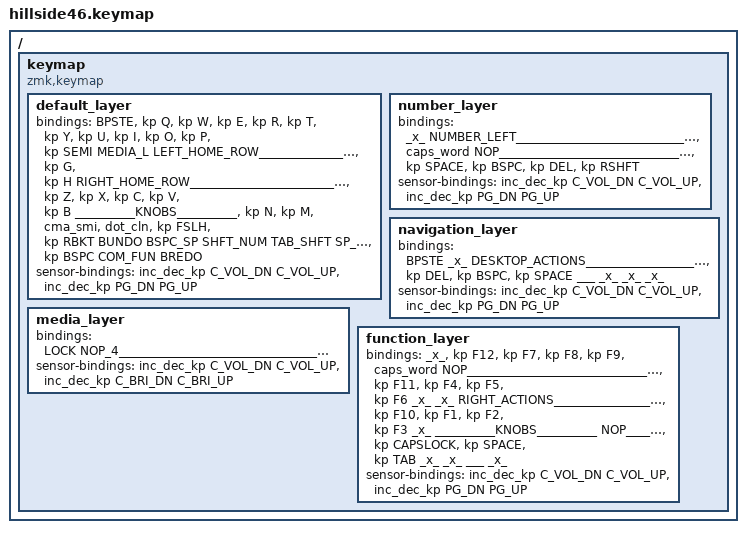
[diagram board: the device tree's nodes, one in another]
/*
 * Copyright (c) 2021-2022 The ZMK Contributors
 *
 * SPDX-License-Identifier: MIT
 */

#include <behaviors.dtsi>
#include <dt-bindings/zmk/bt.h>
#include <dt-bindings/zmk/ext_power.h>
#include <dt-bindings/zmk/keys.h>
#include <dt-bindings/zmk/outputs.h>


// layers
#define DEF     0
#define NUM     1
#define NAV     2
#define MEDIA   3
#define FUN     4

#include "keys/46.h"
#include "includes/macros.dtsi"
#include "includes/combos.dtsi"
#include "includes/behaviors.dtsi"






// Layers toggles       hold     tap
#define MEDIA_L  &ltr   MEDIA    LG(C)
#define MEDIA_R  &ltr   MEDIA    LBKT
#define SP_NAV   &ltr   NAV      SPACE
#define COM_FUN  &ltsk  FUN      LGUI   // sticky
#define SHFT_NUM &ltsk  NUM      LSHFT  // sticky

// Mod taps              hold     tap
#define BSPC_SP   &mt    SPACE    BSPC  
#define TAB_SHFT  &mt    LSHFT    TAB


// shorter codes
#define SCRSHT   &kp  LS(LG(N1))
#define LOCK     &kp  LG(LC(Q))
#define SHENTER  &kp  LS(RET)
#define BPSTE    &kp  LG(V)
#define BCPY     &kp  LG(C)
#define BCUT     &kp  LG(X)
#define BUNDO    &kp  LG(Z)
#define BREDO    &kp  LG(LS(Z))
#define BPREV    &kp  C_PREV
#define BNEXT    &kp  C_NEXT
#define BPLYPSE  &kp  C_PLAY_PAUSE
#define BMUTE    &kp  K_MUTE
#define BSTOP    &kp  C_PLAY_PAUSE
#define BVOLD    &kp  K_VOL_DN
#define BVOLU    &kp  K_VOL_UP
#define BRIUP    &kp  C_BRIGHTNESS_INC
#define BRIDOWN  &kp  C_BRIGHTNESS_DEC
#define MOVERGHT &kp  LC(RIGHT)
#define MOVELEFT &kp  LC(LEFT)
#define SHOWAPPS &kp  LC(UP)
#define MEETING  &kp  LS(LG(J))
#define BLUUSB   &out OUT_TOG // toggle keyboard output bluetooth/usb
#define ___      &trans      //  transparent
#define _x_      &none

// Home row mods
#define HRML(k1, k2, k3, k4) &hml LGUI  k1  &hml LALT  k2 &hml LCTRL k3 &hml LSHFT k4
#define HRMR(k1, k2, k3, k4) &hmr RSHFT k1  &hmr RCTRL k2 &hmr RALT  k3 &hmr RGUI  k4

// 5 Rows
#define NUMBER_TOP_ROW___________________________________  &kp N5    &kp N6    &kp N7    &kp N8    &kp N9   
#define NUMBER_BOTTOM_ROW________________________________  &kp N1    &kp N2    &kp N3    &kp N4    &kp N0
#define NOP______________________________________________    _x_       _x_       _x_       _x_       _x_  
#define PAGE_CONTROL_ROW_________________________________  &kp HOME  &kp PG_DN &kp PG_UP  &kp END  &kp INS    
#define BLUETOOTH________________________________________  &bt BT_PRV  &bt BT_NXT  &out OUT_USB  &out OUT_BLE  &bt BT_CLR_ALL 

// 4 Rows
#define NAVIGATION_____________________________            &kp LEFT  &kp DOWN   &kp UP    &kp RIGHT  
#define LEFT_ACTIONS___________________________            &kp LGUI  &kp LALT   &kp LCTRL &kp LSHFT 
#define RIGHT_ACTIONS__________________________            &kp RSHFT &kp RCTRL  &kp RALT  &kp RGUI
#define DESKTOP_ACTIONS________________________            SHOWAPPS  MOVELEFT  MOVERGHT   &kp LG(SPACE)
#define LEFT_HOME_ROW__________________________            HRML(A,        S,        D,        F)
#define RIGHT_HOME_ROW_________________________            HRMR(J,        K,        L,       SQT)
#define NOP_4__________________________________            _x_         _x_       _x_       _x_


// 3 Rows
#define VOLUME_CONTROL_______________                      BVOLD     BMUTE     BVOLU  
#define PLAY_CONTROL_________________                      BPREV    BPLYPSE    BNEXT 

// Number pad
#define NUMBER_LEFT______________________________________  &kp N1    &kp N2    &kp N3  &kp N4    &kp N5
#define NUMBER_RIGHT_____________________________________  &kp N6    &kp N7    &kp N8  &kp N9    &kp N0

// Knobs
#define __________KNOBS__________  &kp CAPSLOCK   &kp CAPSLOCK
#define _______KNOBS_MEDIA_______  BVOLD          LOCK






/ {
  keymap {
    compatible = "zmk,keymap";
    default_layer { // layer 0 (default)
      bindings = <
//  ╭──────────╭─────────────────────────────────────────────────╮                                 ╭───────────────────────────────────────────────────────────╮
//  │  PASTE   │    Q    │    W    │    E    │    R    │    T    │                                 │    Y    │    U    │    I    │    O    │    P    │   ;:    │
      BPSTE     &kp Q     &kp W     &kp E     &kp R     &kp T                                       &kp Y     &kp U     &kp I     &kp O     &kp P     &kp SEMI
//  ├──────────├─────────┼─────────┼─────────┼─────────┼─────────┤                                 ├─────────┼─────────┼─────────┼─────────┼─────────┤─────────┤
//  │ COPY/ME  │    A    │    S    │    D    │    F    │    G    │                                 │    H    │    J    │    K    │    L    │    '    │LeftBr/ME│
      MEDIA_L   LEFT_HOME_ROW__________________________ &kp G                                       &kp H     RIGHT_HOME_ROW_________________________  MEDIA_R    
//  ├──────────├─────────┼─────────┼─────────┼─────────┼─────────┤                                 ├─────────┼─────────┼─────────┼─────────┼─────────┤─────────┤
//  │   CUT    │    Z    │    X    │    C    │    V    │    B    │   ╭─────────╮     ╭─────────╮   │    N    │    M    │   ,/;   │   ./:   │    /    │ RighBr  │
        BCUT    &kp Z     &kp X     &kp C     &kp V     &kp B         __________KNOBS__________     &kp N     &kp M     &cma_smi  &dot_cln  &kp FSLH   &kp RBKT
//  ├──────────╰─────────┼─────────┼─────────┼─────────┼─────────┼   ╰─────────╯     ╰─────────╯   ┼─────────┼─────────┼─────────┼─────────┼───────────────────╯
                  BUNDO   BSPC_SP  SHFT_NUM  TAB_SHFT                                               SP_NAV  &kp BSPC    COM_FUN    BREDO
//             ╰───────────────────────────────────────╯                                           ╰───────────────────────────────────────╯
      >;

      sensor-bindings = <&inc_dec_kp C_VOL_DN C_VOL_UP &inc_dec_kp PG_DN PG_UP>;
    };


    number_layer { // layer 1 (numbers)
      bindings = <
//  ╭──────────╭─────────────────────────────────────────────────╮                                 ╭───────────────────────────────────────────────────────────╮
//  │          │                                                 │                                 │         │                                                 │ 
        _x_     NUMBER_LEFT______________________________________                                   NUMBER_RIGHT_____________________________________    _x_
//  ├──────────├─────────┼─────────┼─────────┼─────────┼─────────┤                                 ├─────────┼─────────┼─────────┼─────────┼─────────┤─────────┤
//  │          │                                                 │                                 │         │                                                 │
        _x_     NUMBER_RIGHT_____________________________________                                      _x_    RIGHT_ACTIONS__________________________   _x_   
//  ├──────────├─────────┼─────────┼─────────┼─────────┼─────────┤                                 ├─────────┼─────────┼─────────┼─────────┼─────────┤─────────┤
//  │          │                                                 │   ╭─────────╮     ╭─────────╮    │         │                                                 │
    &caps_word  NOP______________________________________________     __________KNOBS__________     NOP______________________________________________   _x_   
//  ├──────────╰─────────┼─────────┼─────────┼─────────┼─────────┼   ╰─────────╯     ╰─────────╯   ┼─────────┼─────────┼─────────┼─────────┼───────────────────╯
                   _x_       _x_       ___       _x_                                             &kp SPACE  &kp BSPC    &kp DEL   &kp RSHFT
//             ╰───────────────────────────────────────╯                                           ╰───────────────────────────────────────╯
      >;

      sensor-bindings = <&inc_dec_kp C_VOL_DN C_VOL_UP &inc_dec_kp PG_DN PG_UP>;
    };



  navigation_layer { // layer 2 (navigation)
      bindings = <
//  ╭──────────╭─────────────────────────────────────────────────╮                                 ╭───────────────────────────────────────────────────────────╮
//  │  PASTE   │         │                                       │                                 │                                                 │         │
      BPSTE        _x_    DESKTOP_ACTIONS________________________                                   NOP______________________________________________    _x_
//  ├──────────├─────────┼─────────┼─────────┼─────────┼─────────┤                                 ├─────────┼─────────┼─────────┼─────────┼─────────┤─────────┤
//  │   COPY   │                                       │         │                                 │                                       │         │         │
       BCPY     LEFT_ACTIONS___________________________   _x_                                       NAVIGATION_____________________________    _x_       _x_    
//  ├──────────├─────────┼─────────┼─────────┼─────────┼─────────┤                                 ├─────────┼─────────┼─────────┼─────────┼─────────┤─────────┤
//  │   CUT    │                                                 │   ╭─────────╮     ╭─────────╮    │                                                 │         │
        BCUT    NOP______________________________________________     __________KNOBS__________     PAGE_CONTROL_ROW_________________________________   _x_
//  ├──────────╰─────────┼─────────┼─────────┼─────────┼─────────┼   ╰─────────╯     ╰─────────╯   ┼─────────┼─────────┼─────────┼─────────┼───────────────────╯
                   _x_    &kp DEL  &kp BSPC &kp SPACE                                                  ___       _x_       _x_       _x_
//             ╰───────────────────────────────────────╯                                           ╰───────────────────────────────────────╯
      >;

      sensor-bindings = <&inc_dec_kp C_VOL_DN C_VOL_UP &inc_dec_kp PG_DN PG_UP>;
    };


    media_layer { // layer 3 (media)
      bindings = <
//  ╭──────────╭─────────────────────────────────────────────────╮                                 ╭───────────────────────────────────────────────────────────╮
//  │   LOCK   │         │                                       │                                 │                                       │         │  LOCK   │
        LOCK     NOP_4__________________________________   _x_                                      NOP_4__________________________________    _x_      LOCK
//  ├──────────├─────────┼─────────┼─────────┼─────────┼─────────┤                                 ├─────────┼─────────┼─────────┼─────────┼─────────┤─────────┤
//  │  MEDIA   │                                                 │                                 │                                                 │  MEDIA  │
        ___        _x_    DESKTOP_ACTIONS________________________                                   DESKTOP_ACTIONS________________________    _x_       ___    
//  ├──────────├─────────┼─────────┼─────────┼─────────┼─────────┤                                 ├─────────┼─────────┼─────────┼─────────┼─────────┤─────────┤
//  │          │                                                 │   ╭─────────╮     ╭─────────╮    │                                                 │         │
        _x_     NOP______________________________________________     _______KNOBS_MEDIA_______    BLUETOOTH________________________________________    _x_
//  ├──────────╰─────────┼─────────┼─────────┼─────────┼─────────┼   ╰─────────╯     ╰─────────╯   ┼─────────┼─────────┼─────────┼─────────┼───────────────────╯
//             │         │                             │                                           │                             │         │
                   _x_    PLAY_CONTROL_________________                                             VOLUME_CONTROL_______________    _x_
//             ╰───────────────────────────────────────╯                                           ╰───────────────────────────────────────╯
      >;

            sensor-bindings = <&inc_dec_kp C_VOL_DN C_VOL_UP &inc_dec_kp C_BRI_DN C_BRI_UP>;
    };

    function_layer { // layer 4 (function)
      bindings = <
//  ╭──────────╭─────────────────────────────────────────────────╮                                 ╭───────────────────────────────────────────────────────────╮
//  │          │   F12   │   F7    │   F8    │   F9    │caps word│                                 │                                                 │         │
        _x_    &kp F12   &kp F7    &kp F8    &kp F9     &caps_word                                  NOP______________________________________________    _x_
//  ├──────────├─────────┼─────────┼─────────┼─────────┼─────────┤                                 ├─────────┼─────────┼─────────┼─────────┼─────────┤─────────┤
//  │          │   F11   │   F4    │   F5    │   F6    │         │                                 │         │                                       │         │
        _x_    &kp F11   &kp F4    &kp F5    &kp F6        _x_                                         _x_    RIGHT_ACTIONS__________________________    _x_    
//  ├──────────├─────────┼─────────┼─────────┼─────────┼─────────┤                                 ├─────────┼─────────┼─────────┼─────────┼─────────┤─────────┤
//  │          │   F10   │   F1    │   F2    │   F3    │         │   ╭─────────╮     ╭─────────╮    │                                                 │         │
        _x_    &kp F10   &kp F1    &kp F2    &kp F3        _x_        __________KNOBS__________     NOP______________________________________________    _x_
//  ├──────────╰─────────┼─────────┼─────────┼─────────┼─────────┼   ╰─────────╯     ╰─────────╯   ┼─────────┼─────────┼─────────┼─────────┼───────────────────╯
                _x_   &kp CAPSLOCK &kp SPACE &kp TAB                                                   _x_       _x_       ___       _x_
//             ╰───────────────────────────────────────╯                                           ╰───────────────────────────────────────╯
      >;

      sensor-bindings = <&inc_dec_kp C_VOL_DN C_VOL_UP &inc_dec_kp PG_DN PG_UP>;
    };

  };
};


